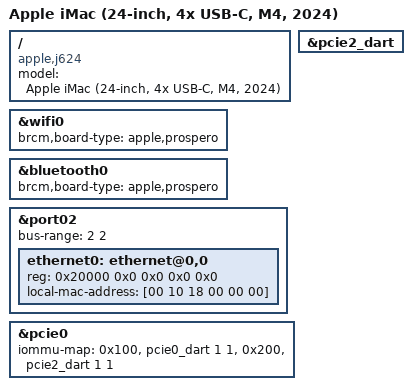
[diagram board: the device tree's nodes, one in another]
// SPDX-License-Identifier: GPL-2.0+ OR MIT
/*
 * Apple iMac (24-inch, 4x USB-C, M4, 2024)
 *
 * target-type: J624
 *
 * Copyright The Asahi Linux Contributors
 */

/dts-v1/;

#include "t8132.dtsi"
#include "t8132-jxxx.dtsi"

/ {
	model = "Apple iMac (24-inch, 4x USB-C, M4, 2024)";
	compatible = "apple,j624", "apple,t8132", "apple,arm-platform";
};

&wifi0 {
	brcm,board-type = "apple,prospero";
};

&bluetooth0 {
	brcm,board-type = "apple,prospero";
};

&port02 {
	bus-range = <2 2>;

	status = "okay";

	ethernet0: ethernet@0,0 {
		reg = <0x20000 0x0 0x0 0x0 0x0>;
		/* To be filled by the loader */
		local-mac-address = [00 10 18 00 00 00];
	};
};

&pcie2_dart {
	status = "okay";
};

&pcie0 {
	iommu-map = <0x100 &pcie0_dart 1 1>,
	            <0x200 &pcie2_dart 1 1>;
};
